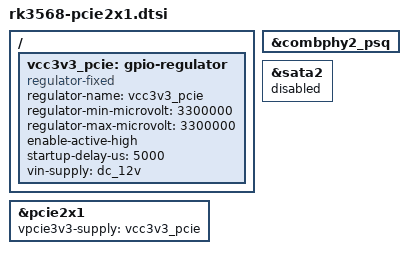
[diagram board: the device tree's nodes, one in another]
/**
 * enable pcie2x1 relavent config for rk3568
 */
 
/ {
	vcc3v3_pcie: gpio-regulator {
		compatible = "regulator-fixed";
		regulator-name = "vcc3v3_pcie";
		regulator-min-microvolt = <3300000>;
		regulator-max-microvolt = <3300000>;
		enable-active-high;
        /**
         * gpio config please refer to main dts if have
		 * gpio = <&gpio* ** ***>;
         */
		startup-delay-us = <5000>;
		vin-supply = <&dc_12v>;
	};

};


&combphy2_psq {
	status = "okay";
};

&sata2 {
    status = "disabled";
};

&pcie2x1 {
    /**
     * gpio please refer to main dts:
	 * reset-gpios = <&gpio* ** ***>;
     */
	vpcie3v3-supply = <&vcc3v3_pcie>;
	status = "okay";
};
